# nrf54h20_enga_application register map
Vendor: Nordic Semiconductor; Series: nRF54h; File version: 1
CPU: CM33 r0p4, little endian, MPU, FPU, 3 interrupt priority bits, 480 interrupts, 4 SAU regions
Registers are 32-bit, read-write, reset 0x0 unless marked. A register's access mark holds for its fields unless they carry their own. Offsets are from the block's base; [hi:lo] are bit positions; lines under a group give offsets from that group; {n}, {i} and the like mark numbered series; 'fields as' and 'values as' point back to an identical list.

## GLOBAL_TWIS130_NS — I2C compatible Two-Wire Slave Interface with EasyDMA 0
Base 0x4F9A5000; alternate view of GLOBAL_SPIM130_NS
Same registers: GLOBAL_TWIS131_NS 0x4F9A6000 (alternate view of GLOBAL_SPIM131_NS), GLOBAL_TWIS132_NS 0x4F9B5000 (alternate view of GLOBAL_SPIM132_NS), GLOBAL_TWIS133_NS 0x4F9B6000 (alternate view of GLOBAL_SPIM133_NS), GLOBAL_TWIS134_NS 0x4F9C5000 (alternate view of GLOBAL_SPIM134_NS), GLOBAL_TWIS135_NS 0x4F9C6000 (alternate view of GLOBAL_SPIM135_NS), GLOBAL_TWIS136_NS 0x4F9D5000 (alternate view of GLOBAL_SPIM136_NS), GLOBAL_TWIS137_NS 0x4F9D6000 (alternate view of GLOBAL_SPIM137_NS), GLOBAL_TWIS130_S 0x5F9A5000 (alternate view of GLOBAL_SPIM130_S), GLOBAL_TWIS131_S 0x5F9A6000 (alternate view of GLOBAL_SPIM131_S), GLOBAL_TWIS132_S 0x5F9B5000 (alternate view of GLOBAL_SPIM132_S), GLOBAL_TWIS133_S 0x5F9B6000 (alternate view of GLOBAL_SPIM133_S), GLOBAL_TWIS134_S 0x5F9C5000 (alternate view of GLOBAL_SPIM134_S), GLOBAL_TWIS135_S 0x5F9C6000 (alternate view of GLOBAL_SPIM135_S), GLOBAL_TWIS136_S 0x5F9D5000 (alternate view of GLOBAL_SPIM136_S), GLOBAL_TWIS137_S 0x5F9D6000 (alternate view of GLOBAL_SPIM137_S)
0x14 TASKS_STOP wo — Stop TWI transaction
  [0] TASKS_STOP
    1=Trigger task
0x1C TASKS_SUSPEND wo — Suspend TWI transaction
  [0] TASKS_SUSPEND
    1=Trigger task
0x20 TASKS_RESUME wo — Resume TWI transaction
  [0] TASKS_RESUME
    1=Trigger task
0x30 TASKS_PREPARERX wo — Prepare the TWI slave to respond to a write command
  [0] TASKS_PREPARERX
    1=Trigger task
0x34 TASKS_PREPARETX wo — Prepare the TWI slave to respond to a read command
  [0] TASKS_PREPARETX
    1=Trigger task
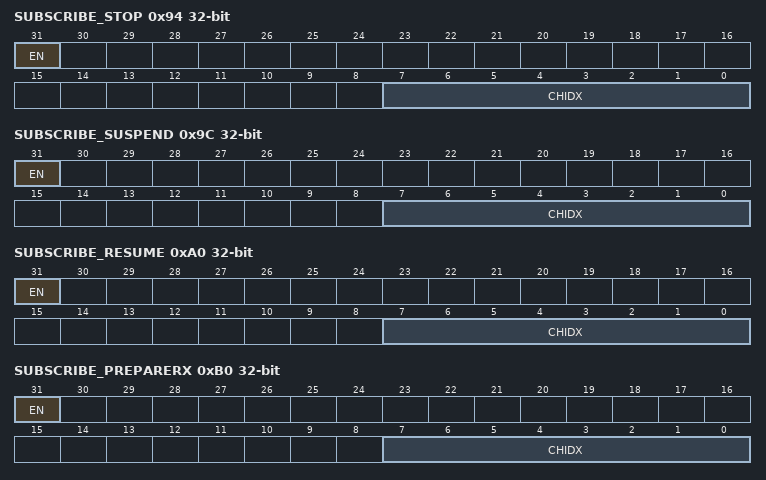
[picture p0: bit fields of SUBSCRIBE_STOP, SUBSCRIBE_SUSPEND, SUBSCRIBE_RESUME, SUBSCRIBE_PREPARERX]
0x94 SUBSCRIBE_STOP — Subscribe configuration for task STOP
  [31] EN
    0=Disabled (Disable subscription); 1=Enabled (Enable subscription)
  [7:0] CHIDX — DPPI channel that task STOP will subscribe to
0x9C SUBSCRIBE_SUSPEND — Subscribe configuration for task SUSPEND
  [31] EN
    values as SUBSCRIBE_STOP.EN
  [7:0] CHIDX — DPPI channel that task SUSPEND will subscribe to
0xA0 SUBSCRIBE_RESUME — Subscribe configuration for task RESUME
  [31] EN
    values as SUBSCRIBE_STOP.EN
  [7:0] CHIDX — DPPI channel that task RESUME will subscribe to
0xB0 SUBSCRIBE_PREPARERX — Subscribe configuration for task PREPARERX
  [31] EN
    values as SUBSCRIBE_STOP.EN
  [7:0] CHIDX — DPPI channel that task PREPARERX will subscribe to
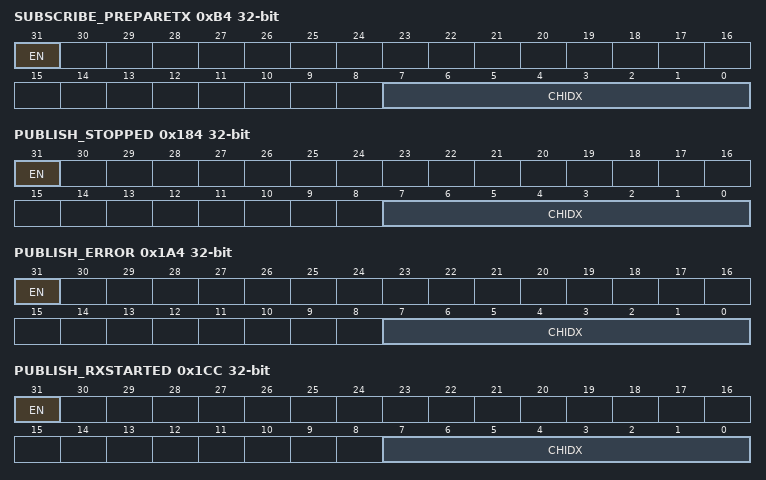
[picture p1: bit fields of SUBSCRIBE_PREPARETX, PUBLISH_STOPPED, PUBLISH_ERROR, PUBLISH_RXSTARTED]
0xB4 SUBSCRIBE_PREPARETX — Subscribe configuration for task PREPARETX
  [31] EN
    values as SUBSCRIBE_STOP.EN
  [7:0] CHIDX — DPPI channel that task PREPARETX will subscribe to
0x104 EVENTS_STOPPED — TWI stopped
  [0] EVENTS_STOPPED
    0=NotGenerated (Event not generated); 1=Generated (Event generated)
0x124 EVENTS_ERROR — TWI error
  [0] EVENTS_ERROR
    values as EVENTS_STOPPED.EVENTS_STOPPED
0x14C EVENTS_RXSTARTED — Receive sequence started
  [0] EVENTS_RXSTARTED
    values as EVENTS_STOPPED.EVENTS_STOPPED
0x150 EVENTS_TXSTARTED — Transmit sequence started
  [0] EVENTS_TXSTARTED
    values as EVENTS_STOPPED.EVENTS_STOPPED
0x164 EVENTS_WRITE — Write command received
  [0] EVENTS_WRITE
    values as EVENTS_STOPPED.EVENTS_STOPPED
0x168 EVENTS_READ — Read command received
  [0] EVENTS_READ
    values as EVENTS_STOPPED.EVENTS_STOPPED
0x174 EVENTS_RXBUSERROR — This event is generated if an error occurs during the bus transfer.
  [0] EVENTS_RXBUSERROR
    values as EVENTS_STOPPED.EVENTS_STOPPED
0x178 EVENTS_TXBUSERROR — This event is generated if an error occurs during the bus transfer.
  [0] EVENTS_TXBUSERROR
    values as EVENTS_STOPPED.EVENTS_STOPPED
0x184 PUBLISH_STOPPED — Publish configuration for event STOPPED
  [31] EN
    0=Disabled (Disable publishing); 1=Enabled (Enable publishing)
  [7:0] CHIDX — DPPI channel that event STOPPED will publish to
0x1A4 PUBLISH_ERROR — Publish configuration for event ERROR
  [31] EN
    values as PUBLISH_STOPPED.EN
  [7:0] CHIDX — DPPI channel that event ERROR will publish to
0x1CC PUBLISH_RXSTARTED — Publish configuration for event RXSTARTED
  [31] EN
    values as PUBLISH_STOPPED.EN
  [7:0] CHIDX — DPPI channel that event RXSTARTED will publish to
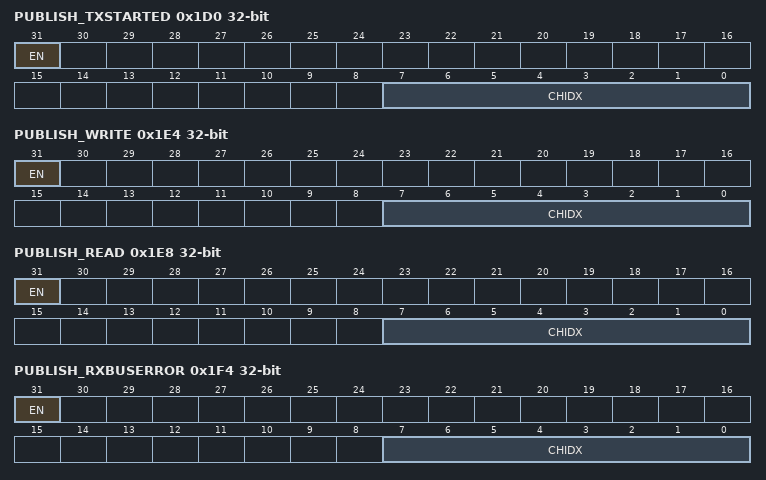
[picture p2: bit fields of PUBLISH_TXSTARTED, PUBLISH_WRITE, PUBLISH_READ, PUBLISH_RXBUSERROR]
0x1D0 PUBLISH_TXSTARTED — Publish configuration for event TXSTARTED
  [31] EN
    values as PUBLISH_STOPPED.EN
  [7:0] CHIDX — DPPI channel that event TXSTARTED will publish to
0x1E4 PUBLISH_WRITE — Publish configuration for event WRITE
  [31] EN
    values as PUBLISH_STOPPED.EN
  [7:0] CHIDX — DPPI channel that event WRITE will publish to
0x1E8 PUBLISH_READ — Publish configuration for event READ
  [31] EN
    values as PUBLISH_STOPPED.EN
  [7:0] CHIDX — DPPI channel that event READ will publish to
0x1F4 PUBLISH_RXBUSERROR — Publish configuration for event RXBUSERROR
  [31] EN
    values as PUBLISH_STOPPED.EN
  [7:0] CHIDX — DPPI channel that event RXBUSERROR will publish to
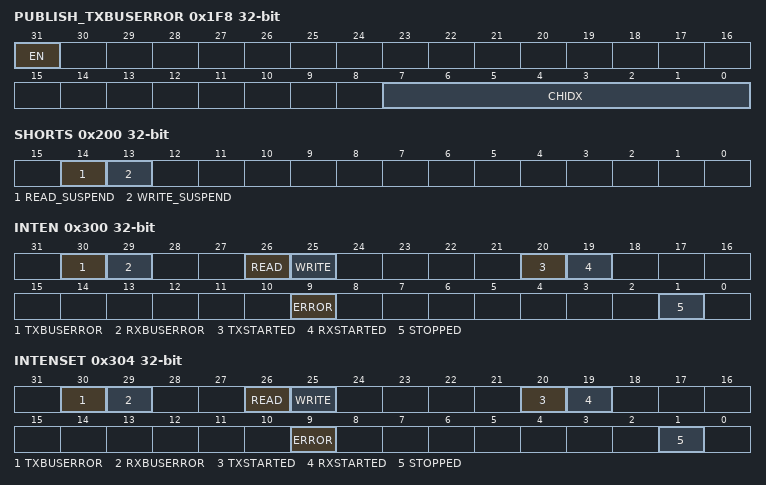
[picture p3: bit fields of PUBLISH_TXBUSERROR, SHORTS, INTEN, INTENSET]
0x1F8 PUBLISH_TXBUSERROR — Publish configuration for event TXBUSERROR
  [31] EN
    values as PUBLISH_STOPPED.EN
  [7:0] CHIDX — DPPI channel that event TXBUSERROR will publish to
0x200 SHORTS — Shortcuts between local events and tasks
  [14] READ_SUSPEND — Shortcut between event READ and task SUSPEND
    0=Disabled (Disable shortcut); 1=Enabled (Enable shortcut)
  [13] WRITE_SUSPEND — Shortcut between event WRITE and task SUSPEND
    0=Disabled (Disable shortcut); 1=Enabled (Enable shortcut)
0x300 INTEN — Enable or disable interrupt
  [all] fields
    0=Disabled; 1=Enabled
  [30] TXBUSERROR — Enable or disable interrupt for event TXBUSERROR
  [29] RXBUSERROR — Enable or disable interrupt for event RXBUSERROR
  [26] READ — Enable or disable interrupt for event READ
  [25] WRITE — Enable or disable interrupt for event WRITE
  [20] TXSTARTED — Enable or disable interrupt for event TXSTARTED
  [19] RXSTARTED — Enable or disable interrupt for event RXSTARTED
  [9] ERROR — Enable or disable interrupt for event ERROR
  [1] STOPPED — Enable or disable interrupt for event STOPPED
0x304 INTENSET — Enable interrupt
  [all] fields
    on read: 0=Disabled (Read: Disabled); 1=Enabled (Read: Enabled) | on write: 1=Set (Enable)
  [30] TXBUSERROR — Write '1' to enable interrupt for event TXBUSERROR
  [29] RXBUSERROR — Write '1' to enable interrupt for event RXBUSERROR
  [26] READ — Write '1' to enable interrupt for event READ
  [25] WRITE — Write '1' to enable interrupt for event WRITE
  [20] TXSTARTED — Write '1' to enable interrupt for event TXSTARTED
  [19] RXSTARTED — Write '1' to enable interrupt for event RXSTARTED
  [9] ERROR — Write '1' to enable interrupt for event ERROR
  [1] STOPPED — Write '1' to enable interrupt for event STOPPED
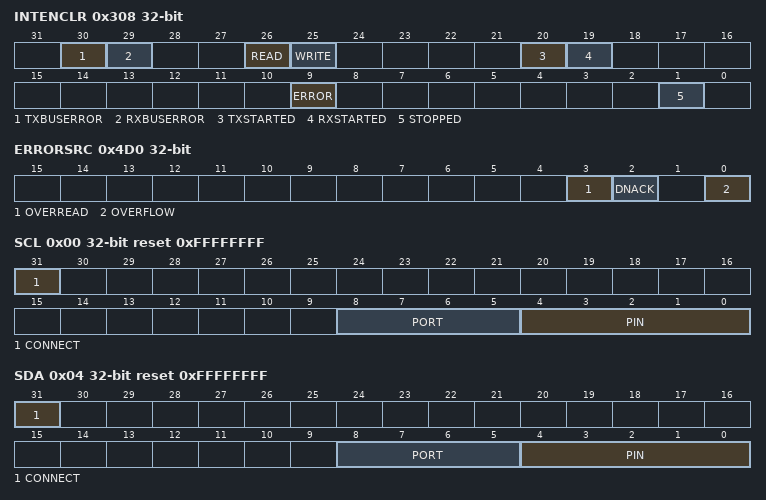
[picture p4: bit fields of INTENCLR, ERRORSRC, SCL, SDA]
0x308 INTENCLR — Disable interrupt
  [all] fields
    on read: 0=Disabled (Read: Disabled); 1=Enabled (Read: Enabled) | on write: 1=Clear (Disable)
  [30] TXBUSERROR — Write '1' to disable interrupt for event TXBUSERROR
  [29] RXBUSERROR — Write '1' to disable interrupt for event RXBUSERROR
  [26] READ — Write '1' to disable interrupt for event READ
  [25] WRITE — Write '1' to disable interrupt for event WRITE
  [20] TXSTARTED — Write '1' to disable interrupt for event TXSTARTED
  [19] RXSTARTED — Write '1' to disable interrupt for event RXSTARTED
  [9] ERROR — Write '1' to disable interrupt for event ERROR
  [1] STOPPED — Write '1' to disable interrupt for event STOPPED
0x4D0 ERRORSRC write-1-clears — Error source
  [3] OVERREAD — TX buffer over-read detected, and prevented
    0=NotDetected (Error did not occur); 1=Detected (Error occurred)
  [2] DNACK — NACK sent after receiving a data byte
    0=NotReceived (Error did not occur); 1=Received (Error occurred)
  [0] OVERFLOW — RX buffer overflow detected, and prevented
    values as OVERREAD
0x4D4 MATCH ro — Status register indicating which address had a match
  [0] MATCH — Indication of which address in ADDRESS that matched the incoming address
0x500 ENABLE — Enable TWIS
  [3:0] ENABLE — Enable or disable TWIS
    0=Disabled (Disable TWIS); 9=Enabled (Enable TWIS)
0x508 PSEL group — Unspecified
  0x00 SCL reset 0xFFFFFFFF — Pin select for SCL signal
    [31] CONNECT — Connection
      1=Disconnected; 0=Connected
    [8:5] PORT — Port number
    [4:0] PIN — Pin number
  0x04 SDA reset 0xFFFFFFFF — Pin select for SDA signal
    fields as PSEL.SCL
0x534 RXD group — RXD EasyDMA channel
  0x00 PTR — RXD Data pointer
  0x04 MAXCNT — Maximum number of bytes in RXD buffer
    [14:0] MAXCNT
  0x08 AMOUNT ro — Number of bytes transferred in the last RXD transaction
    [14:0] AMOUNT
  0x0C LIST — EasyDMA list type
    [1:0] LIST — List type
      0=Disabled (Disable EasyDMA list); 1=ArrayList (Use array list)
0x544 TXD group — TXD EasyDMA channel
  0x00 PTR — TXD Data pointer
  0x04 MAXCNT — Maximum number of bytes in TXD buffer
    [14:0] MAXCNT
  0x08 AMOUNT ro — Number of bytes transferred in the last TXD transaction
    [14:0] AMOUNT
  0x0C LIST — EasyDMA list type
    fields as RXD.LIST
{0x588+4i} ADDRESS[{i}] (i=0..1) — Description collection: TWI slave address n
  [6:0] ADDRESS — TWI slave address
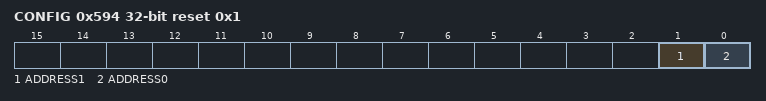
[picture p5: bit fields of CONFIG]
0x594 CONFIG reset 0x1 — Configuration register for the address match mechanism
  [1] ADDRESS1 — Enable or disable address matching on ADDRESS[1]
    0=Disabled; 1=Enabled
  [0] ADDRESS0 — Enable or disable address matching on ADDRESS[0]
    0=Disabled; 1=Enabled
0x5B0 DMA group — Unspecified
  0x00 RX group — Unspecified
    0x00 TERMINATEONBUSERROR — Terminate the transaction if a BUSERROR event is detected.
      [0] ENABLE
        0=Disabled; 1=Enabled
    0x04 BUSERRORADDRESS ro — Address of transaction that generated the last BUSERROR event.
      [31:0] ADDRESS
  0x08 TX group — Unspecified
    0x00 TERMINATEONBUSERROR — Terminate the transaction if a BUSERROR event is detected.
      [0] ENABLE
        0=Disabled; 1=Enabled
    0x04 BUSERRORADDRESS ro — Address of transaction that generated the last BUSERROR event.
      [31:0] ADDRESS
0x5C0 ORC — Over-read character. Character sent out in case of an over-read of the transmit buffer.
  [7:0] ORC
